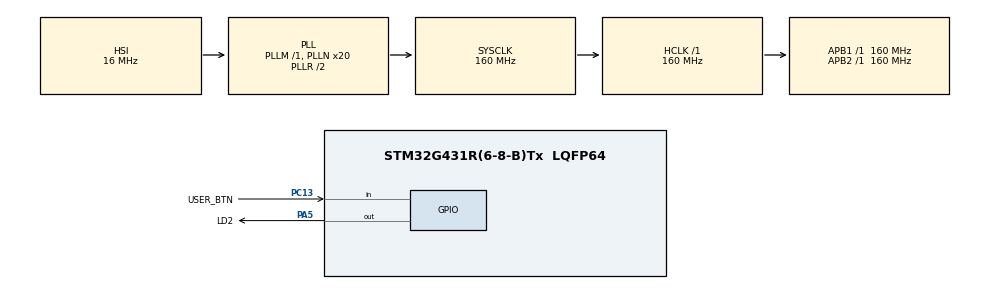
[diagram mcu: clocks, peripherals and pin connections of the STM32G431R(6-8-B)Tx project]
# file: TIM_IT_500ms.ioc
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Mcu.Family=STM32G4
Mcu.Name=STM32G431R(6-8-B)Tx
Mcu.Package=LQFP64
NUCLEO-G431RB.Bsp_Common_DEMO=true
NVIC.PriorityGroup=NVIC_PRIORITYGROUP_4
NVIC.TIM6_DAC_IRQn=true\:5\:0\:true\:false\:true\:true\:true\:true
PA13.GPIO_Label=T_SWDIO
PA13.Mode=Serial_Wire
PA13.Signal=SYS_JTMS-SWDIO
PA14.GPIO_Label=T_SWCLK
PA14.Mode=Serial_Wire
PA14.Signal=SYS_JTCK-SWCLK
PA5.GPIO_Label=LD2
PA5.Signal=GPIO_Output
PC13.GPIO_Label=USER_BTN
PC13.Signal=GPIO_Input
ProjectManager.HeapSize=0x200
ProjectManager.StackSize=0x400
ProjectManager.TargetToolchain=CMake
RCC.ADC12Freq_Value=160000000
RCC.AHBFreq_Value=160000000
RCC.APB1Freq_Value=160000000
RCC.APB1TimFreq_Value=160000000
RCC.APB2Freq_Value=160000000
RCC.APB2TimFreq_Value=160000000
RCC.CortexFreq_Value=160000000
RCC.EXTERNAL_CLOCK_VALUE=12288000
RCC.HCLKFreq_Value=160000000
RCC.HSE_VALUE=24000000
RCC.HSI48_VALUE=48000000
RCC.HSI_VALUE=16000000
RCC.LSE_VALUE=32768
RCC.PLLN=20
RCC.RTCClockSelection=RCC_RTCCLKSOURCE_LSE
RCC.SYSCLKFreq_VALUE=160000000
RCC.SYSCLKSource=RCC_SYSCLKSOURCE_PLLCLK
RCC.USBFreq_Value=160000000
RCC.VCOOutputFreq_Value=320000000
TIM6.PeriodNoDither=49999
TIM6.Prescaler=1599
VP_NUCLEO-G431RB_VS_BSP_COMMON.Mode=COMMON
VP_SYS_VS_DBSignals.Mode=DisableDeadBatterySignals
VP_TIM6_VS_ClockSourceINT.Mode=Enable_Timer
board=NUCLEO-G431RB

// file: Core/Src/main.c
/* USER CODE BEGIN Header */
/**
  ******************************************************************************
  * @file           : main.c
  * @brief          : Main program body
  ******************************************************************************
  * @attention
  *
  * Copyright (c) 2026 STMicroelectronics.
  * All rights reserved.
  *
  * This software is licensed under terms that can be found in the LICENSE file
  * in the root directory of this software component.
  * If no LICENSE file comes with this software, it is provided AS-IS.
  *
  ******************************************************************************
  */
/* USER CODE END Header */
#include "main.h"

__IO uint32_t BspButtonState = BUTTON_RELEASED;
TIM_HandleTypeDef htim6;

void SystemClock_Config(void);
static void MX_GPIO_Init(void);
static void MX_TIM6_Init(void);

int main(void)
{

  /* MCU Configuration--------------------------------------------------------*/

  /* Reset of all peripherals, Initializes the Flash interface and the Systick. */
  HAL_Init();

  /* Configure the system clock */
  SystemClock_Config();

  /* Initialize all configured peripherals */
  MX_GPIO_Init();
  MX_TIM6_Init();
  /* USER CODE BEGIN 2 */
  HAL_TIM_Base_Start_IT(&htim6);
  /* USER CODE END 2 */

  /* Infinite loop */
  while (1)
  {

  }
}

void SystemClock_Config(void)
{
  RCC_OscInitTypeDef RCC_OscInitStruct = {0};
  RCC_ClkInitTypeDef RCC_ClkInitStruct = {0};

  /** Configure the main internal regulator output voltage
  */
  HAL_PWREx_ControlVoltageScaling(PWR_REGULATOR_VOLTAGE_SCALE1_BOOST);

  /** Initializes the RCC Oscillators according to the specified parameters
  * in the RCC_OscInitTypeDef structure.
  */
  RCC_OscInitStruct.OscillatorType = RCC_OSCILLATORTYPE_HSI;
  RCC_OscInitStruct.HSIState = RCC_HSI_ON;
  RCC_OscInitStruct.HSICalibrationValue = RCC_HSICALIBRATION_DEFAULT;
  RCC_OscInitStruct.PLL.PLLState = RCC_PLL_ON;
  RCC_OscInitStruct.PLL.PLLSource = RCC_PLLSOURCE_HSI;
  RCC_OscInitStruct.PLL.PLLM = RCC_PLLM_DIV1;
  RCC_OscInitStruct.PLL.PLLN = 20;
  RCC_OscInitStruct.PLL.PLLP = RCC_PLLP_DIV2;
  RCC_OscInitStruct.PLL.PLLQ = RCC_PLLQ_DIV2;
  RCC_OscInitStruct.PLL.PLLR = RCC_PLLR_DIV2;
  if (HAL_RCC_OscConfig(&RCC_OscInitStruct) != HAL_OK)
  {
    Error_Handler();
  }

  /** Initializes the CPU, AHB and APB buses clocks
  */
  RCC_ClkInitStruct.ClockType = RCC_CLOCKTYPE_HCLK|RCC_CLOCKTYPE_SYSCLK
                              |RCC_CLOCKTYPE_PCLK1|RCC_CLOCKTYPE_PCLK2;
  RCC_ClkInitStruct.SYSCLKSource = RCC_SYSCLKSOURCE_PLLCLK;
  RCC_ClkInitStruct.AHBCLKDivider = RCC_SYSCLK_DIV1;
  RCC_ClkInitStruct.APB1CLKDivider = RCC_HCLK_DIV1;
  RCC_ClkInitStruct.APB2CLKDivider = RCC_HCLK_DIV1;

  if (HAL_RCC_ClockConfig(&RCC_ClkInitStruct, FLASH_LATENCY_4) != HAL_OK)
  {
    Error_Handler();
  }
}

static void MX_TIM6_Init(void)
{

  TIM_MasterConfigTypeDef sMasterConfig = {0};

  htim6.Instance = TIM6;
  htim6.Init.Prescaler = 1599;
  htim6.Init.CounterMode = TIM_COUNTERMODE_UP;
  htim6.Init.Period = 49999;
  htim6.Init.AutoReloadPreload = TIM_AUTORELOAD_PRELOAD_DISABLE;
  if (HAL_TIM_Base_Init(&htim6) != HAL_OK)
  {
    Error_Handler();
  }
  sMasterConfig.MasterOutputTrigger = TIM_TRGO_RESET;
  sMasterConfig.MasterSlaveMode = TIM_MASTERSLAVEMODE_DISABLE;
  if (HAL_TIMEx_MasterConfigSynchronization(&htim6, &sMasterConfig) != HAL_OK)
  {
    Error_Handler();
  }

}

static void MX_GPIO_Init(void)
{
  GPIO_InitTypeDef GPIO_InitStruct = {0};

  /* GPIO Ports Clock Enable */
  __HAL_RCC_GPIOC_CLK_ENABLE();
  __HAL_RCC_GPIOA_CLK_ENABLE();

  /*Configure GPIO pin Output Level */
  HAL_GPIO_WritePin(LD2_GPIO_Port, LD2_Pin, GPIO_PIN_RESET);

  /*Configure GPIO pin : USER_BTN_Pin */
  GPIO_InitStruct.Pin = USER_BTN_Pin;
  GPIO_InitStruct.Mode = GPIO_MODE_INPUT;
  GPIO_InitStruct.Pull = GPIO_NOPULL;
  HAL_GPIO_Init(USER_BTN_GPIO_Port, &GPIO_InitStruct);

  /*Configure GPIO pin : LD2_Pin */
  GPIO_InitStruct.Pin = LD2_Pin;
  GPIO_InitStruct.Mode = GPIO_MODE_OUTPUT_PP;
  GPIO_InitStruct.Pull = GPIO_NOPULL;
  GPIO_InitStruct.Speed = GPIO_SPEED_FREQ_LOW;
  HAL_GPIO_Init(LD2_GPIO_Port, &GPIO_InitStruct);

}

/* USER CODE BEGIN 4 */

/**
  * @brief  Period elapsed callback in non-blocking mode
  * @param  htim: TIM handle
  * @retval None
  */
void HAL_TIM_PeriodElapsedCallback(TIM_HandleTypeDef *htim)
{
  if (htim->Instance == TIM6)
  {
    HAL_GPIO_TogglePin(LD2_GPIO_Port, LD2_Pin);
  }
}

/* USER CODE END 4 */

void Error_Handler(void)
{
  __disable_irq();
  while (1)
  {
  }
}
